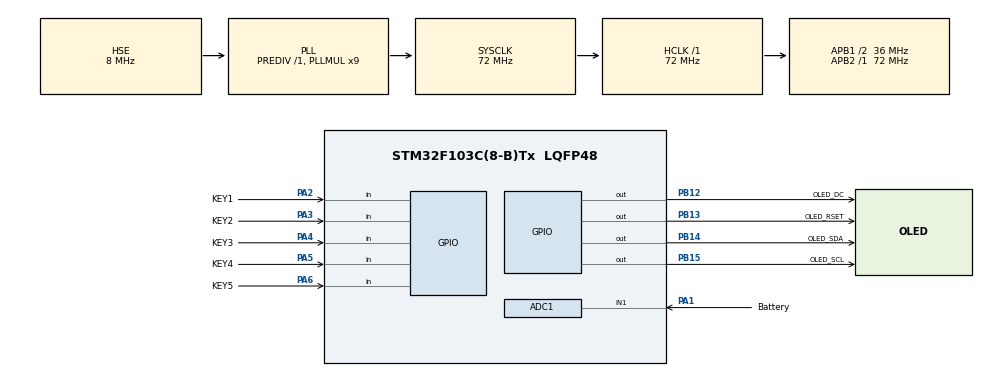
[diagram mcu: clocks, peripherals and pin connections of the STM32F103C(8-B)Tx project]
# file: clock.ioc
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ADC1.Channel-0\#ChannelRegularConversion=ADC_CHANNEL_1
ADC1.ContinuousConvMode=ENABLE
ADC1.NbrOfConversionFlag=1
ADC1.Rank-0\#ChannelRegularConversion=1
ADC1.SamplingTime-0\#ChannelRegularConversion=ADC_SAMPLETIME_1CYCLE_5
ADC1.master=1
Mcu.Family=STM32F1
Mcu.Name=STM32F103C(8-B)Tx
Mcu.Package=LQFP48
NVIC.PriorityGroup=NVIC_PRIORITYGROUP_4
NVIC.RTC_IRQn=true\:0\:0\:false\:false\:true\:true\:true
NVIC.TIM4_IRQn=true\:0\:0\:false\:false\:true\:false\:true
NVIC.TimeBase=TIM4_IRQn
NVIC.TimeBaseIP=TIM4
PA1.GPIO_Label=Battery
PA1.Signal=ADCx_IN1
PA13.Mode=Serial_Wire
PA13.Signal=SYS_JTMS-SWDIO
PA14.Mode=Serial_Wire
PA14.Signal=SYS_JTCK-SWCLK
PA2.GPIO_Label=KEY1
PA2.GPIO_PuPd=GPIO_PULLUP
PA2.Signal=GPIO_Input
PA3.GPIO_Label=KEY2
PA3.GPIO_PuPd=GPIO_PULLUP
PA3.Signal=GPIO_Input
PA4.GPIO_Label=KEY3
PA4.GPIO_PuPd=GPIO_PULLUP
PA4.Signal=GPIO_Input
PA5.GPIO_Label=KEY4
PA5.GPIO_PuPd=GPIO_PULLUP
PA5.Signal=GPIO_Input
PA6.GPIO_Label=KEY5
PA6.GPIO_PuPd=GPIO_PULLUP
PA6.Signal=GPIO_Input
PB12.GPIO_Label=OLED_DC
PB12.PinState=GPIO_PIN_SET
PB12.Signal=GPIO_Output
PB13.GPIO_Label=OLED_RSET
PB13.PinState=GPIO_PIN_SET
PB13.Signal=GPIO_Output
PB14.GPIO_Label=OLED_SDA
PB14.PinState=GPIO_PIN_SET
PB14.Signal=GPIO_Output
PB15.GPIO_Label=OLED_SCL
PB15.PinState=GPIO_PIN_SET
PB15.Signal=GPIO_Output
PD0-OSC_IN.Mode=HSE-External-Oscillator
PD0-OSC_IN.Signal=RCC_OSC_IN
PD1-OSC_OUT.Mode=HSE-External-Oscillator
PD1-OSC_OUT.Signal=RCC_OSC_OUT
ProjectManager.HeapSize=0x200
ProjectManager.StackSize=0x400
ProjectManager.TargetToolchain=MDK-ARM V5.27
RCC.ADCPresc=RCC_ADCPCLK2_DIV6
RCC.AHBFreq_Value=72000000
RCC.APB1CLKDivider=RCC_HCLK_DIV2
RCC.APB1Freq_Value=36000000
RCC.APB1TimFreq_Value=72000000
RCC.APB2Freq_Value=72000000
RCC.APB2TimFreq_Value=72000000
RCC.HCLKFreq_Value=72000000
RCC.PLLMUL=RCC_PLL_MUL9
RCC.PLLSourceVirtual=RCC_PLLSOURCE_HSE
RCC.SYSCLKFreq_VALUE=72000000
RCC.SYSCLKSource=RCC_SYSCLKSOURCE_PLLCLK
RCC.USBFreq_Value=72000000
SH.ADCx_IN1.0=ADC1_IN1,IN1
VP_RTC_VS_RTC_Activate.Mode=RTC_Enabled
VP_SYS_VS_tim4.Mode=TIM4
board=custom

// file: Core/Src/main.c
/* USER CODE BEGIN Header */
/**
  ******************************************************************************
  * @file           : main.c
  * @brief          : Main program body
  ******************************************************************************
  * @attention
  *
  * <h2><center>&copy; Copyright (c) 2022 STMicroelectronics.
  * All rights reserved.</center></h2>
  *
  * This software component is licensed by ST under BSD 3-Clause license,
  * the "License"; You may not use this file except in compliance with the
  * License. You may obtain a copy of the License at:
  *                        opensource.org/licenses/BSD-3-Clause
  *
  ******************************************************************************
  */
/* USER CODE END Header */
#include "main.h"

/* USER CODE BEGIN Includes */
#include "oled.h"
#include "key.h"

#include "draw.h"
#include "display.h"
#include "clock.h"
#include "bms.h"

/* USER CODE END Includes */

ADC_HandleTypeDef hadc1;

RTC_HandleTypeDef hrtc;

void SystemClock_Config(void);
static void MX_GPIO_Init(void);
static void MX_ADC1_Init(void);
static void MX_RTC_Init(void);

int main(void)
{

  /* MCU Configuration--------------------------------------------------------*/

  /* Reset of all peripherals, Initializes the Flash interface and the Systick. */
  HAL_Init();

  /* Configure the system clock */
  SystemClock_Config();

  /* Initialize all configured peripherals */
  MX_GPIO_Init();
  MX_ADC1_Init();
  MX_RTC_Init();
  /* USER CODE BEGIN 2 */
	oled_init();
	bms_init();
	clock_init();
  /* USER CODE END 2 */

  /* Infinite loop */
  /* USER CODE BEGIN WHILE */
  while (1)
  {
		clock_loop();
		bms_get_voltage();
    /* USER CODE END WHILE */

  }
}

void SystemClock_Config(void)
{
  RCC_OscInitTypeDef RCC_OscInitStruct = {0};
  RCC_ClkInitTypeDef RCC_ClkInitStruct = {0};
  RCC_PeriphCLKInitTypeDef PeriphClkInit = {0};

  /** Initializes the RCC Oscillators according to the specified parameters
  * in the RCC_OscInitTypeDef structure.
  */
  RCC_OscInitStruct.OscillatorType = RCC_OSCILLATORTYPE_LSI|RCC_OSCILLATORTYPE_HSE;
  RCC_OscInitStruct.HSEState = RCC_HSE_ON;
  RCC_OscInitStruct.HSEPredivValue = RCC_HSE_PREDIV_DIV1;
  RCC_OscInitStruct.HSIState = RCC_HSI_ON;
  RCC_OscInitStruct.LSIState = RCC_LSI_ON;
  RCC_OscInitStruct.PLL.PLLState = RCC_PLL_ON;
  RCC_OscInitStruct.PLL.PLLSource = RCC_PLLSOURCE_HSE;
  RCC_OscInitStruct.PLL.PLLMUL = RCC_PLL_MUL9;
  if (HAL_RCC_OscConfig(&RCC_OscInitStruct) != HAL_OK)
  {
    Error_Handler();
  }
  /** Initializes the CPU, AHB and APB buses clocks
  */
  RCC_ClkInitStruct.ClockType = RCC_CLOCKTYPE_HCLK|RCC_CLOCKTYPE_SYSCLK
                              |RCC_CLOCKTYPE_PCLK1|RCC_CLOCKTYPE_PCLK2;
  RCC_ClkInitStruct.SYSCLKSource = RCC_SYSCLKSOURCE_PLLCLK;
  RCC_ClkInitStruct.AHBCLKDivider = RCC_SYSCLK_DIV1;
  RCC_ClkInitStruct.APB1CLKDivider = RCC_HCLK_DIV2;
  RCC_ClkInitStruct.APB2CLKDivider = RCC_HCLK_DIV1;

  if (HAL_RCC_ClockConfig(&RCC_ClkInitStruct, FLASH_LATENCY_2) != HAL_OK)
  {
    Error_Handler();
  }
  PeriphClkInit.PeriphClockSelection = RCC_PERIPHCLK_RTC|RCC_PERIPHCLK_ADC;
  PeriphClkInit.RTCClockSelection = RCC_RTCCLKSOURCE_LSI;
  PeriphClkInit.AdcClockSelection = RCC_ADCPCLK2_DIV6;
  if (HAL_RCCEx_PeriphCLKConfig(&PeriphClkInit) != HAL_OK)
  {
    Error_Handler();
  }
}

static void MX_ADC1_Init(void)
{

  ADC_ChannelConfTypeDef sConfig = {0};

  /** Common config
  */
  hadc1.Instance = ADC1;
  hadc1.Init.ScanConvMode = ADC_SCAN_DISABLE;
  hadc1.Init.ContinuousConvMode = ENABLE;
  hadc1.Init.DiscontinuousConvMode = DISABLE;
  hadc1.Init.ExternalTrigConv = ADC_SOFTWARE_START;
  hadc1.Init.DataAlign = ADC_DATAALIGN_RIGHT;
  hadc1.Init.NbrOfConversion = 1;
  if (HAL_ADC_Init(&hadc1) != HAL_OK)
  {
    Error_Handler();
  }
  /** Configure Regular Channel
  */
  sConfig.Channel = ADC_CHANNEL_1;
  sConfig.Rank = ADC_REGULAR_RANK_1;
  sConfig.SamplingTime = ADC_SAMPLETIME_1CYCLE_5;
  if (HAL_ADC_ConfigChannel(&hadc1, &sConfig) != HAL_OK)
  {
    Error_Handler();
  }

}

static void MX_RTC_Init(void)
{

  /** Initialize RTC Only
  */
  hrtc.Instance = RTC;
  hrtc.Init.AsynchPrediv = RTC_AUTO_1_SECOND;
  hrtc.Init.OutPut = RTC_OUTPUTSOURCE_ALARM;
  if (HAL_RTC_Init(&hrtc) != HAL_OK)
  {
    Error_Handler();
  }

}

static void MX_GPIO_Init(void)
{
  GPIO_InitTypeDef GPIO_InitStruct = {0};

  /* GPIO Ports Clock Enable */
  __HAL_RCC_GPIOD_CLK_ENABLE();
  __HAL_RCC_GPIOA_CLK_ENABLE();
  __HAL_RCC_GPIOB_CLK_ENABLE();

  /*Configure GPIO pin Output Level */
  HAL_GPIO_WritePin(GPIOB, OLED_DC_Pin|OLED_RSET_Pin|OLED_SDA_Pin|OLED_SCL_Pin, GPIO_PIN_SET);

  /*Configure GPIO pins : KEY1_Pin KEY2_Pin KEY3_Pin KEY4_Pin
                           KEY5_Pin */
  GPIO_InitStruct.Pin = KEY1_Pin|KEY2_Pin|KEY3_Pin|KEY4_Pin
                          |KEY5_Pin;
  GPIO_InitStruct.Mode = GPIO_MODE_INPUT;
  GPIO_InitStruct.Pull = GPIO_PULLUP;
  HAL_GPIO_Init(GPIOA, &GPIO_InitStruct);

  /*Configure GPIO pins : OLED_DC_Pin OLED_RSET_Pin OLED_SDA_Pin OLED_SCL_Pin */
  GPIO_InitStruct.Pin = OLED_DC_Pin|OLED_RSET_Pin|OLED_SDA_Pin|OLED_SCL_Pin;
  GPIO_InitStruct.Mode = GPIO_MODE_OUTPUT_PP;
  GPIO_InitStruct.Pull = GPIO_NOPULL;
  GPIO_InitStruct.Speed = GPIO_SPEED_FREQ_LOW;
  HAL_GPIO_Init(GPIOB, &GPIO_InitStruct);

}

 /**
  * @brief  Period elapsed callback in non blocking mode
  * @note   This function is called  when TIM4 interrupt took place, inside
  * HAL_TIM_IRQHandler(). It makes a direct call to HAL_IncTick() to increment
  * a global variable "uwTick" used as application time base.
  * @param  htim : TIM handle
  * @retval None
  */
void HAL_TIM_PeriodElapsedCallback(TIM_HandleTypeDef *htim)
{
  if (htim->Instance == TIM4) {
    HAL_IncTick();
  }
}

void Error_Handler(void)
{
  __disable_irq();
  while (1)
  {
  }
}

/************************ (C) COPYRIGHT STMicroelectronics *****END OF FILE****/
